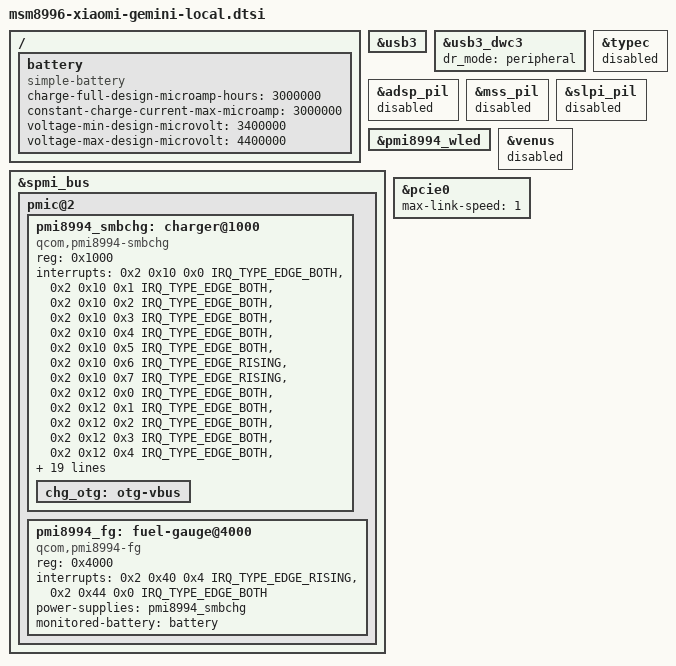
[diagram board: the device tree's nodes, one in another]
// SPDX-License-Identifier: BSD-3-Clause
/*
 * Local gemini tweaks for Linux 7.0, from:
 * - live dump 2026-08-27 (Synaptics S3330, JDI 1080x1920, 3000 mAh battery)
 * - umeko 6.1.14 / msm8996-mainline (board-id 32)
 * - Kernel-Build ginkgo bring-up pattern (do not steal BT UART for console)
 */
#include <dt-bindings/interrupt-controller/irq.h>

/ {
	/* blsp1_uart2 on gemini is QCA6174 BT, not a debug console.
	 * Do not set stdout-path there — earlycon/ttyMSM0 on 0x7570000 hangs.
	 */
	battery: battery {
		compatible = "simple-battery";
		charge-full-design-microamp-hours = <3000000>;
		constant-charge-current-max-microamp = <3000000>;
		voltage-min-design-microvolt = <3400000>;
		voltage-max-design-microvolt = <4400000>;
	};
};

/* Fastboot already put the port in device mode. tusb320 extcon can defer
 * DWC3 forever (no UDC → no ACM). Drop extcon and force gadget. */
&usb3 {
	/delete-property/ extcon;
};

&usb3_dwc3 {
	dr_mode = "peripheral";
	/delete-property/ extcon;
};

&typec {
	status = "disabled";
};

/* umeko gemini.note.md: ADSP (and Note2 mss/slpi) firmware load hangs boot.
 * 7.0 has these built-in (umeko 6.1 had =m), so disable until USB is up. */
&adsp_pil {
	status = "disabled";
};

&mss_pil {
	status = "disabled";
};

&slpi_pil {
	status = "disabled";
};

/* GPU must stay enabled: 6.1 dmesg shows msm_mdp waits to bind b00000.gpu
 * before [drm] Initialized / msmdrmfb. Disabling GPU leaves the LK splash. */

/*
 * Reboot to fastboot = Kernel-Build: `reboot bootloader`.
 * pm8994 already has mode-bootloader = <0x2>. Do not add qcom,pshold@4ab000
 * and do not ioremap IMEM (boot-time syscon and reboot-time /dev/mem both hung).
 */

/* umeko 6.1 never got WLED OVP irq. 7.0 resolving it then enable_irq from
 * wled_ovp_work oops'd because LK left the backlight module enabled. */
&pmi8994_wled {
	/delete-property/ interrupts;
	/delete-property/ interrupt-names;
};

/* venus firmware is on userdata; builtin probe leaves mmcc/qnoc
 * sync_state pending on c00000.video-codec and stalls the log screen. */
&venus {
	status = "disabled";
};

/* PMI8994 SMBCHG + FG from msm8996-mainline. Upstream 7.0 pmi8994.dtsi
 * has neither node. Merge onto pmic@2 (SID 2). FG gives current_now. */
&spmi_bus {
	pmic@2 {
		pmi8994_smbchg: charger@1000 {
			compatible = "qcom,pmi8994-smbchg";
			reg = <0x1000>;

			interrupts = <0x2 0x10 0x0 IRQ_TYPE_EDGE_BOTH>,
				     <0x2 0x10 0x1 IRQ_TYPE_EDGE_BOTH>,
				     <0x2 0x10 0x2 IRQ_TYPE_EDGE_BOTH>,
				     <0x2 0x10 0x3 IRQ_TYPE_EDGE_BOTH>,
				     <0x2 0x10 0x4 IRQ_TYPE_EDGE_BOTH>,
				     <0x2 0x10 0x5 IRQ_TYPE_EDGE_BOTH>,
				     <0x2 0x10 0x6 IRQ_TYPE_EDGE_RISING>,
				     <0x2 0x10 0x7 IRQ_TYPE_EDGE_RISING>,
				     <0x2 0x12 0x0 IRQ_TYPE_EDGE_BOTH>,
				     <0x2 0x12 0x1 IRQ_TYPE_EDGE_BOTH>,
				     <0x2 0x12 0x2 IRQ_TYPE_EDGE_BOTH>,
				     <0x2 0x12 0x3 IRQ_TYPE_EDGE_BOTH>,
				     <0x2 0x12 0x4 IRQ_TYPE_EDGE_BOTH>,
				     <0x2 0x12 0x5 IRQ_TYPE_EDGE_BOTH>,
				     <0x2 0x12 0x6 IRQ_TYPE_EDGE_BOTH>,
				     <0x2 0x12 0x7 IRQ_TYPE_EDGE_BOTH>,
				     <0x2 0x13 0x0 IRQ_TYPE_EDGE_BOTH>,
				     <0x2 0x13 0x1 IRQ_TYPE_EDGE_BOTH>,
				     <0x2 0x13 0x2 IRQ_TYPE_EDGE_BOTH>,
				     <0x2 0x13 0x3 IRQ_TYPE_EDGE_BOTH>,
				     <0x2 0x13 0x4 IRQ_TYPE_EDGE_RISING>,
				     <0x2 0x13 0x5 IRQ_TYPE_EDGE_RISING>,
				     <0x2 0x13 0x6 IRQ_TYPE_EDGE_FALLING>,
				     <0x2 0x14 0x0 IRQ_TYPE_EDGE_BOTH>,
				     <0x2 0x14 0x1 IRQ_TYPE_EDGE_BOTH>,
				     <0x2 0x16 0x0 IRQ_TYPE_EDGE_BOTH>,
				     <0x2 0x16 0x1 IRQ_TYPE_EDGE_BOTH>,
				     <0x2 0x16 0x2 IRQ_TYPE_EDGE_BOTH>,
				     <0x2 0x16 0x3 IRQ_TYPE_EDGE_BOTH>,
				     <0x2 0x16 0x4 IRQ_TYPE_EDGE_BOTH>,
				     <0x2 0x16 0x5 IRQ_TYPE_EDGE_BOTH>;
			interrupt-names = "chg-error",
					  "chg-inhibit",
					  "chg-prechg-sft",
					  "chg-complete-chg-sft",
					  "chg-p2f-thr",
					  "chg-rechg-thr",
					  "chg-taper-thr",
					  "chg-tcc-thr",
					  "batt-hot",
					  "batt-warm",
					  "batt-cold",
					  "batt-cool",
					  "batt-ov",
					  "batt-low",
					  "batt-missing",
					  "batt-term-missing",
					  "usbin-uv",
					  "usbin-ov",
					  "usbin-src-det",
					  "otg-fail",
					  "otg-oc",
					  "aicl-done",
					  "usbid-change",
					  "dcin-uv",
					  "dcin-ov",
					  "power-ok",
					  "temp-shutdown",
					  "wdog-timeout",
					  "flash-fail",
					  "otst2",
					  "otst3";

			monitored-battery = <&battery>;
			status = "okay";

			chg_otg: otg-vbus { };
		};

		pmi8994_fg: fuel-gauge@4000 {
			compatible = "qcom,pmi8994-fg";
			reg = <0x4000>;

			interrupts = <0x2 0x40 0x4 IRQ_TYPE_EDGE_RISING>,
				     <0x2 0x44 0x0 IRQ_TYPE_EDGE_BOTH>;
			interrupt-names = "soc-delta", "mem-avail";

			power-supplies = <&pmi8994_smbchg>;
			monitored-battery = <&battery>;
			status = "okay";
		};
	};
};

/*
 * QCA6174 on gemini. 6.1 trained PCIe Gen.1 x1 in ~100 ms. 7.0 default
 * TLS is Gen2 (5.0 GT/s); LTSSM stuck in POLL ("Device found, but not
 * active"), no 0000:01:00.0 / wlp1s0. Software retrain does not recover;
 * next boot must start at Gen1. PERST retry is in pcie-qcom (msm8996).
 */
&pcie0 {
	max-link-speed = <1>;
};
